VERSION ""

NS_ :

BS_:

BU_: XXX

BO_ 85 CID_FUPSWT: 8 XXX
 SG_ sig_khpeiq : 40|1@1+ (1,0) [0|1] "" XXX
 SG_ sig_ccaecv : 56|8@1+ (1,0) [0|255] "" XXX

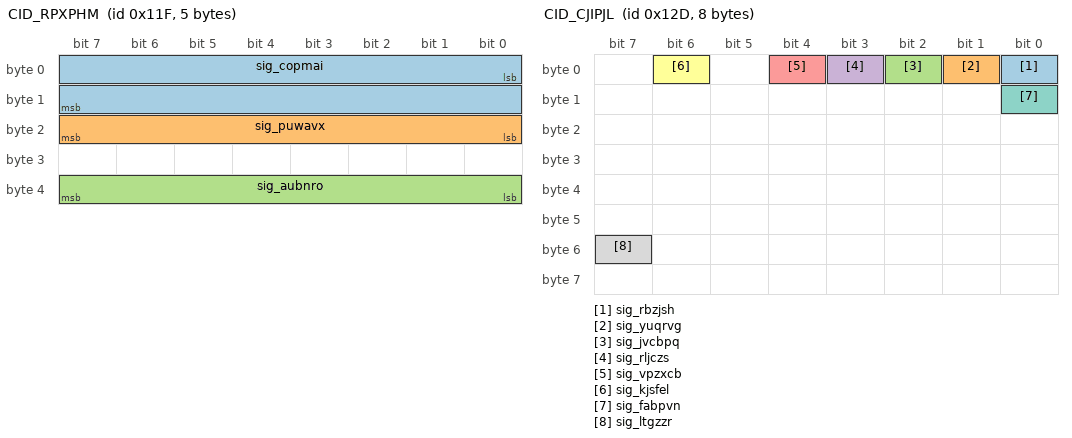
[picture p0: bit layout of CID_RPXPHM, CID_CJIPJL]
BO_ 287 CID_RPXPHM: 5 XXX
 SG_ sig_copmai : 0|16@1- (0.1,0) [-450|450] "" XXX
 SG_ sig_puwavx : 16|8@1+ (4,0) [0|1020] "" XXX
 SG_ sig_aubnro : 32|8@1+ (1,0) [0|255] "" XXX

BO_ 289 CID_MSTLHB: 8 XXX
 SG_ sig_lrkbzq : 0|12@1+ (1,0) [0|255] "" XXX

BO_ 301 CID_CJIPJL: 8 XXX
 SG_ sig_rbzjsh : 0|1@0+ (1,0) [0|1] "" XXX
 SG_ sig_yuqrvg : 1|1@0+ (1,0) [0|1] "" XXX
 SG_ sig_jvcbpq : 2|1@0+ (1,0) [0|1] "" XXX
 SG_ sig_rljczs : 3|1@0+ (1,0) [0|1] "" XXX
 SG_ sig_vpzxcb : 4|1@0+ (1,0) [0|1] "" XXX
 SG_ sig_kjsfel : 6|1@0+ (1,0) [0|1] "" XXX
 SG_ sig_fabpvn : 8|1@0+ (1,0) [0|1] "" XXX
 SG_ sig_ltgzzr : 55|1@0+ (1,0) [0|1] "" XXX

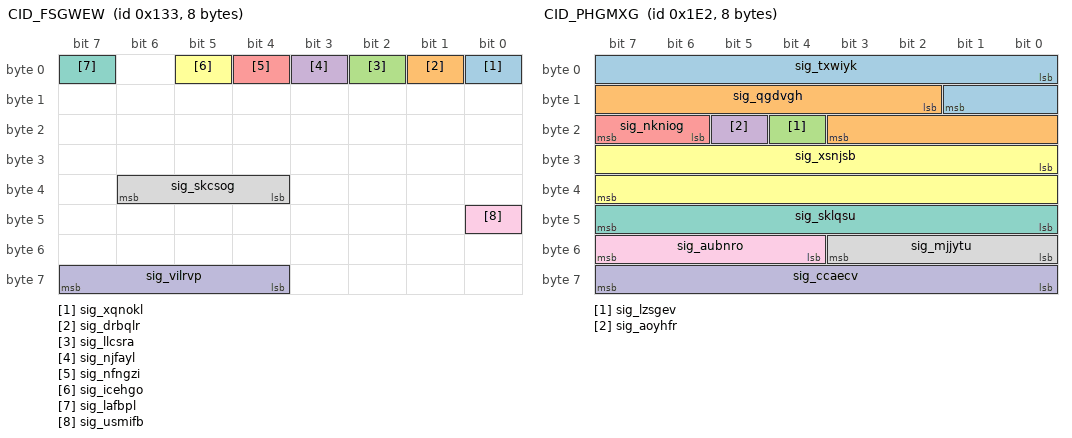
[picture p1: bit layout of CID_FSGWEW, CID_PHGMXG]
BO_ 307 CID_FSGWEW: 8 XXX
 SG_ sig_xqnokl : 0|1@0+ (1,0) [0|1] "" XXX
 SG_ sig_drbqlr : 1|1@1+ (1,0) [0|1] "" XXX
 SG_ sig_llcsra : 2|1@1+ (1,0) [0|1] "" XXX
 SG_ sig_njfayl : 3|1@1+ (1,0) [0|1] "" XXX
 SG_ sig_nfngzi : 4|1@0+ (1,0) [0|1] "" XXX
 SG_ sig_icehgo : 5|1@0+ (1,0) [0|1] "" XXX
 SG_ sig_lafbpl : 7|1@0+ (1,0) [0|1] "" XXX
 SG_ sig_skcsog : 36|3@1+ (1,0) [0|7] "" XXX
 SG_ sig_usmifb : 40|1@0+ (1,0) [0|1] "" XXX
 SG_ sig_vilrvp : 63|4@0+ (1,0) [0|15] "" XXX

BO_ 482 CID_PHGMXG: 8 XXX
 SG_ sig_txwiyk : 0|10@1- (0.01,0) [0|5] "" XXX
 SG_ sig_qgdvgh : 10|10@1- (0.01,0) [-5|0] "" XXX
 SG_ sig_lzsgev : 20|1@0+ (1,0) [0|1] "" XXX
 SG_ sig_aoyhfr : 21|1@0+ (1,0) [0|1] "" XXX
 SG_ sig_nkniog : 22|2@1+ (1,0) [0|1] "" XXX
 SG_ sig_xsnjsb : 24|16@1- (0.1,0) [-780|779.9] "" XXX
 SG_ sig_sklqsu : 47|8@0+ (1,0) [0|255] "" XXX
 SG_ sig_mjjytu : 48|4@1+ (1,0) [0|15] "" XXX
 SG_ sig_aubnro : 52|4@1+ (1,0) [0|15] "" XXX
 SG_ sig_ccaecv : 56|8@1+ (1,0) [0|255] "" XXX

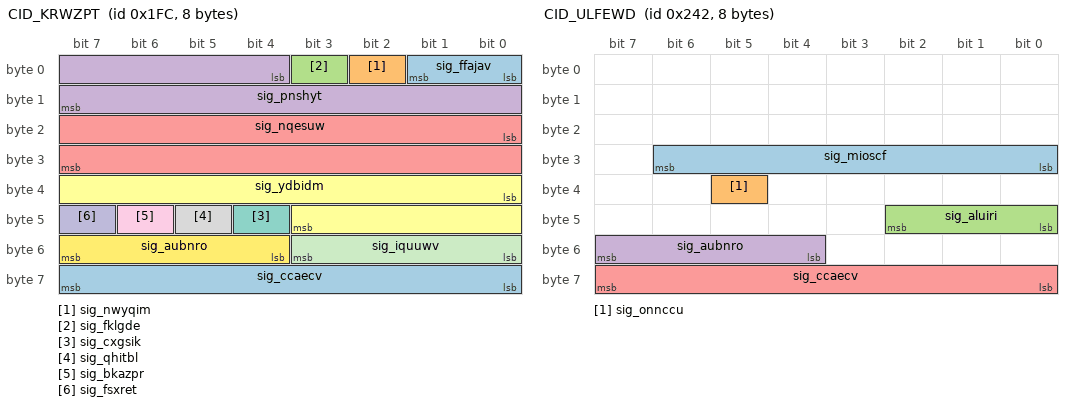
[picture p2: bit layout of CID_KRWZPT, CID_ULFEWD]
BO_ 508 CID_KRWZPT: 8 XXX
 SG_ sig_ffajav : 0|2@1+ (1,0) [0|1] "" XXX
 SG_ sig_nwyqim : 2|1@1+ (1,0) [0|1] "" XXX
 SG_ sig_fklgde : 3|1@0+ (1,0) [0|1] "" XXX
 SG_ sig_pnshyt : 4|12@1- (1,0) [-2048|2047] "" XXX
 SG_ sig_nqesuw : 16|16@1- (0.1,0) [-780|779.9] "Deg" XXX
 SG_ sig_ydbidm : 32|12@1- (0.01,0) [0|63] "" XXX
 SG_ sig_cxgsik : 44|1@0+ (1,0) [0|1] "" XXX
 SG_ sig_qhitbl : 45|1@1+ (1,0) [0|255] "" XXX
 SG_ sig_bkazpr : 46|1@1+ (1,0) [0|1] "" XXX
 SG_ sig_fsxret : 47|1@0+ (1,0) [0|3] "" XXX
 SG_ sig_iquuwv : 48|4@1+ (1,0) [0|15] "" XXX
 SG_ sig_aubnro : 52|4@1+ (1,0) [0|15] "" XXX
 SG_ sig_ccaecv : 56|8@1+ (1,0) [0|255] "" XXX

BO_ 578 CID_ULFEWD: 8 XXX
 SG_ sig_mioscf : 30|7@0+ (1,0) [0|127] "" XXX
 SG_ sig_onnccu : 37|1@0+ (1,0) [0|1] "" XXX
 SG_ sig_aluiri : 40|3@1+ (1,0) [0|7] "" XXX
 SG_ sig_aubnro : 55|4@0+ (1,0) [0|15] "" XXX
 SG_ sig_ccaecv : 56|8@1+ (1,0) [0|255] "" XXX

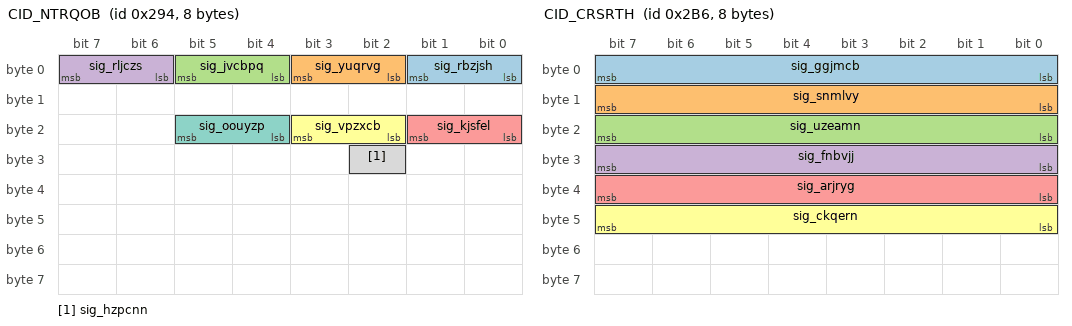
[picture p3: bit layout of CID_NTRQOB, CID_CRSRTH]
BO_ 660 CID_NTRQOB: 8 XXX
 SG_ sig_rbzjsh : 1|2@0+ (1,0) [0|3] "" XXX
 SG_ sig_yuqrvg : 3|2@0+ (1,0) [0|3] "" XXX
 SG_ sig_jvcbpq : 5|2@0+ (1,0) [0|3] "" XXX
 SG_ sig_rljczs : 7|2@0+ (1,0) [0|3] "" XXX
 SG_ sig_kjsfel : 17|2@0+ (1,0) [0|3] "" XXX
 SG_ sig_vpzxcb : 19|2@0+ (1,0) [0|3] "" XXX
 SG_ sig_oouyzp : 21|2@0+ (1,0) [0|3] "" XXX
 SG_ sig_hzpcnn : 26|1@0+ (1,0) [0|1] "" XXX

BO_ 694 CID_CRSRTH: 8 XXX
 SG_ sig_ggjmcb : 7|8@0+ (1,0) [0|255] "" XXX
 SG_ sig_snmlvy : 15|8@0+ (1,0) [0|255] "" XXX
 SG_ sig_uzeamn : 23|8@0+ (1,0) [0|255] "" XXX
 SG_ sig_fnbvjj : 31|8@0+ (1,0) [0|255] "" XXX
 SG_ sig_arjryg : 39|8@0+ (1,0) [0|255] "" XXX
 SG_ sig_ckqern : 47|8@0+ (1,0) [0|255] "" XXX

BO_ 790 CID_AKQXAC: 8 XXX
 SG_ sig_mhqcfa : 3|4@0+ (1,0) [0|1] "" XXX
 SG_ sig_szzntf : 4|2@1+ (1,0) [0|3] "" XXX
 SG_ sig_bfdwya : 6|2@1+ (1,0) [0|3] "" XXX
 SG_ sig_bmkikb : 8|2@1+ (1,0) [0|3] "" XXX
 SG_ sig_znuqhe : 10|1@1+ (1,0) [0|1] "" XXX
 SG_ sig_elygmq : 11|4@1+ (1,0) [0|1] "" XXX
 SG_ sig_vcobfx : 15|1@0+ (1,0) [0|1] "" XXX
 SG_ sig_xsnjsb : 16|11@1- (1,0) [-1024|1023] "" XXX
 SG_ sig_lzsgev : 27|1@1+ (1,0) [0|1] "" XXX
 SG_ sig_aoyhfr : 28|1@1+ (1,0) [0|3] "" XXX
 SG_ sig_pcgoix : 29|1@0+ (1,0) [0|1] "" XXX
 SG_ sig_iuokvo : 30|1@0+ (1,0) [0|1] "" XXX
 SG_ sig_aeodfr : 31|1@0+ (1,0) [0|1] "" XXX
 SG_ sig_twling : 32|2@1+ (1,0) [0|3] "" XXX
 SG_ sig_plttoo : 34|2@1+ (1,0) [0|3] "" XXX
 SG_ sig_azepww : 36|4@1+ (1,0) [0|3] "" XXX
 SG_ sig_navtqm : 40|8@1+ (5,-5) [-5|1270] "" XXX
 SG_ sig_laolyo : 49|2@0+ (1,0) [0|3] "" XXX
 SG_ sig_perogx : 51|2@0+ (1,0) [0|3] "" XXX
 SG_ sig_aubnro : 52|4@1+ (1,0) [0|15] "" XXX
 SG_ sig_ccaecv : 56|8@1+ (1,0) [0|15] "" XXX

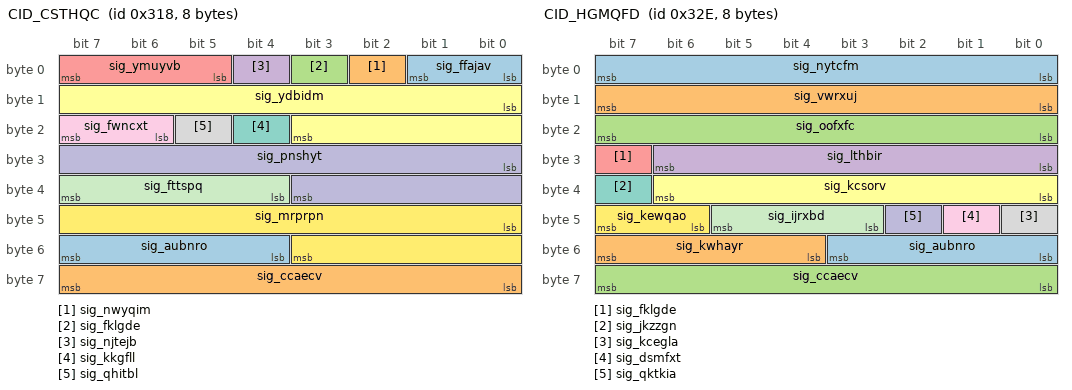
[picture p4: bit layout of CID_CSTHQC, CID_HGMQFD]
BO_ 792 CID_CSTHQC: 8 XXX
 SG_ sig_ffajav : 0|2@1+ (1,0) [0|1] "" XXX
 SG_ sig_nwyqim : 2|1@1+ (1,0) [0|1] "" XXX
 SG_ sig_fklgde : 3|1@1+ (1,0) [0|1] "" XXX
 SG_ sig_njtejb : 4|1@1+ (1,0) [0|1] "" XXX
 SG_ sig_ymuyvb : 5|3@1+ (1,0) [0|1] "" XXX
 SG_ sig_ydbidm : 8|12@1- (1,0) [-2048|2047] "" XXX
 SG_ sig_kkgfll : 20|1@1+ (1,0) [0|1] "" XXX
 SG_ sig_qhitbl : 21|1@1+ (1,0) [0|1] "" XXX
 SG_ sig_fwncxt : 22|2@1+ (1,0) [0|15] "" XXX
 SG_ sig_pnshyt : 24|12@1- (1,0) [-2048|2047] "" XXX
 SG_ sig_fttspq : 36|4@1+ (1,0) [0|15] "" XXX
 SG_ sig_mrprpn : 40|12@1+ (1,0) [0|4095] "" XXX
 SG_ sig_aubnro : 52|4@1+ (1,0) [0|15] "" XXX
 SG_ sig_ccaecv : 56|8@1+ (1,0) [0|255] "" XXX

BO_ 813 CID_YJGMTI: 8 XXX
 SG_ sig_ginhwr : 0|9@1+ (0.5,0) [0|255.5] "" XXX
 SG_ sig_tvsgqb : 9|1@1+ (1,0) [0|1] "" XXX
 SG_ sig_ncymwn : 10|3@1+ (1,0) [0|7] "" XXX
 SG_ sig_urxhdo : 13|3@1+ (1,0) [0|7] "" XXX
 SG_ sig_tgcotr : 16|1@1+ (1,0) [0|1] "" XXX
 SG_ sig_zpaojq : 17|1@1+ (1,0) [0|1] "" XXX
 SG_ sig_fklgde : 18|1@1+ (1,0) [0|1] "" XXX
 SG_ sig_uancac : 19|3@1+ (1,0) [0|1] "" XXX
 SG_ sig_steqoi : 22|1@0+ (1,0) [0|1] "" XXX
 SG_ sig_bkwvyy : 23|1@0+ (1,0) [0|1] "" XXX
 SG_ sig_bmkikb : 24|1@1+ (1,0) [0|1] "" XXX
 SG_ sig_ssfjhn : 25|7@1+ (1,0) [0|127] "" XXX
 SG_ sig_bxhmbj : 32|4@1+ (1,0) [0|15] "" XXX
 SG_ sig_ezfuol : 36|12@1+ (1,0) [0|4095] "" XXX
 SG_ sig_aubnro : 48|4@1+ (1,0) [0|15] "" XXX
 SG_ sig_pblzjk : 55|4@0+ (1,0) [0|15] "" XXX
 SG_ sig_ccaecv : 56|8@1+ (1,0) [0|255] "" XXX

BO_ 814 CID_HGMQFD: 8 XXX
 SG_ sig_nytcfm : 0|8@1+ (0.05,-5) [-100|155] "" XXX
 SG_ sig_vwrxuj : 8|8@1+ (0.05,-5) [0|1.26] "" XXX
 SG_ sig_oofxfc : 16|8@1+ (0.05,-5) [0|1.26] "" XXX
 SG_ sig_lthbir : 24|7@1+ (0.2,0) [0|12.7] "" XXX
 SG_ sig_fklgde : 31|1@0+ (1,0) [0|1] "" XXX
 SG_ sig_kcsorv : 32|7@1+ (0.2,-16) [0|12.7] "" XXX
 SG_ sig_jkzzgn : 39|1@0+ (1,0) [0|1] "" XXX
 SG_ sig_kcegla : 40|1@0+ (1,0) [0|1] "" XXX
 SG_ sig_dsmfxt : 41|1@0+ (1,0) [0|1] "" XXX
 SG_ sig_qktkia : 42|1@1+ (1,0) [0|3] "" XXX
 SG_ sig_ijrxbd : 45|3@0+ (1,0) [0|1] "" XXX
 SG_ sig_kewqao : 46|2@1+ (1,0) [0|3] "" XXX
 SG_ sig_aubnro : 48|4@1+ (1,0) [0|15] "" XXX
 SG_ sig_kwhayr : 55|4@0+ (1,0) [0|15] "" XXX
 SG_ sig_ccaecv : 56|8@1+ (1,0) [0|255] "" XXX

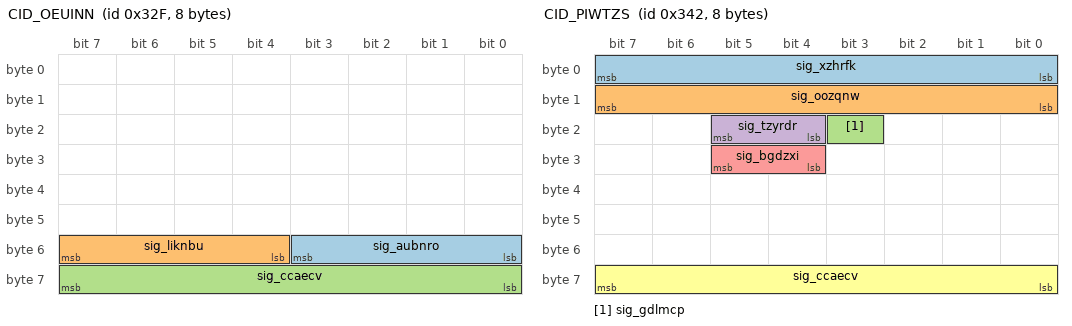
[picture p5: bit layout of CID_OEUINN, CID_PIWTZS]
BO_ 815 CID_OEUINN: 8 XXX
 SG_ sig_aubnro : 48|4@1+ (1,0) [0|15] "" XXX
 SG_ sig_liknbu : 55|4@0+ (1,0) [0|15] "" XXX
 SG_ sig_ccaecv : 56|8@1+ (1,0) [0|255] "" XXX

BO_ 834 CID_PIWTZS: 8 XXX
 SG_ sig_xzhrfk : 0|8@1+ (0.01,0) [0|2.55] "" XXX
 SG_ sig_oozqnw : 8|8@1+ (0.01,0) [0|2.55] "" XXX
 SG_ sig_gdlmcp : 19|1@1+ (1,0) [0|1] "" XXX
 SG_ sig_tzyrdr : 20|2@1+ (1,0) [0|255] "" XXX
 SG_ sig_bgdzxi : 28|2@1+ (1,0) [0|1] "" XXX
 SG_ sig_ccaecv : 56|8@1+ (1,0) [0|255] "" XXX

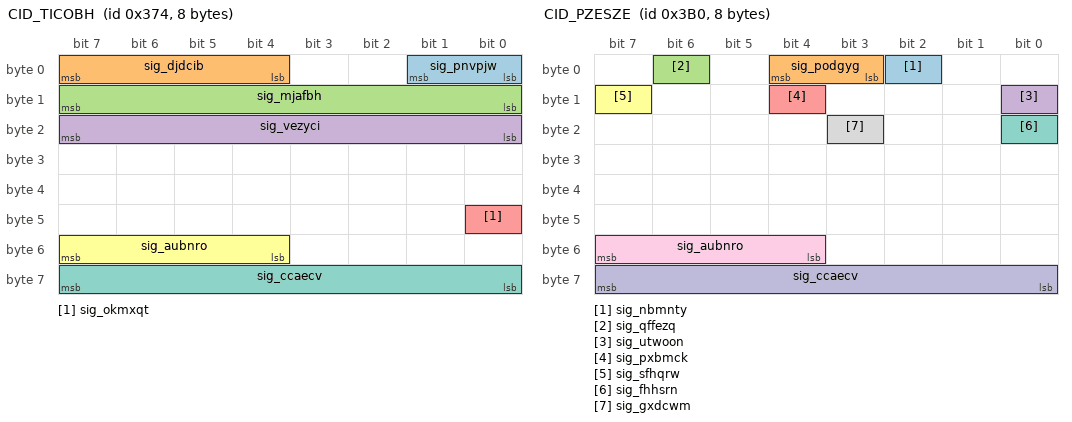
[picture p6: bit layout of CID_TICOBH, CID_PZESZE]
BO_ 884 CID_TICOBH: 8 XXX
 SG_ sig_pnvpjw : 1|2@0+ (1,0) [0|3] "" XXX
 SG_ sig_djdcib : 7|4@0+ (1,0) [0|15] "" XXX
 SG_ sig_mjafbh : 15|8@0+ (0.1,-12) [0|255] "" XXX
 SG_ sig_vezyci : 23|8@0+ (1,-100) [0|255] "" XXX
 SG_ sig_okmxqt : 40|1@0+ (1,0) [0|3] "" XXX
 SG_ sig_aubnro : 52|4@1+ (1,0) [0|15] "" XXX
 SG_ sig_ccaecv : 56|8@1+ (1,0) [0|255] "" XXX

BO_ 944 CID_PZESZE: 8 XXX
 SG_ sig_nbmnty : 2|1@0+ (1,0) [0|1] "" XXX
 SG_ sig_podgyg : 4|2@0+ (1,0) [0|3] "" XXX
 SG_ sig_qffezq : 6|1@0+ (1,0) [0|1] "" XXX
 SG_ sig_utwoon : 8|1@0+ (1,0) [0|1] "" XXX
 SG_ sig_pxbmck : 12|1@0+ (1,0) [0|1] "" XXX
 SG_ sig_sfhqrw : 15|1@0+ (1,0) [0|1] "" XXX
 SG_ sig_fhhsrn : 16|1@0+ (1,0) [0|1] "" XXX
 SG_ sig_gxdcwm : 19|1@0+ (1,0) [0|1] "" XXX
 SG_ sig_aubnro : 52|4@1+ (1,0) [0|15] "" XXX
 SG_ sig_ccaecv : 56|8@1+ (1,0) [0|255] "" XXX

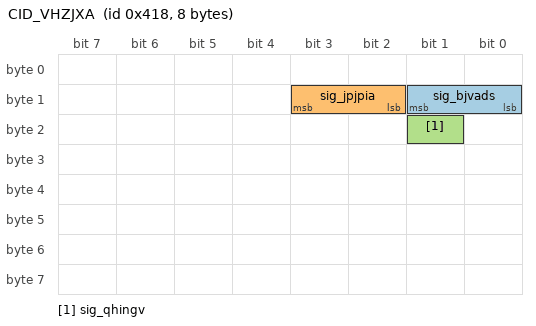
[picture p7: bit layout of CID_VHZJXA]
BO_ 1048 CID_VHZJXA: 8 XXX
 SG_ sig_bjvads : 9|2@0+ (1,0) [0|1] "" XXX
 SG_ sig_jpjpia : 11|2@0+ (1,0) [0|1] "" XXX
 SG_ sig_qhingv : 17|1@0+ (1,0) [0|1] "" XXX

VAL_ 578 sig_aluiri 4 "D" 2 "R" 3 "N" 1 "P";
VAL_ 790 sig_mhqcfa 11 "AutoFullBeamActive" 2 "AutoFullBeamInactive";
VAL_ 790 sig_szzntf 0 "GRAY" 1 "GREEN" 2 "YELLOW" 3 "RED";
VAL_ 790 sig_bfdwya 3 "ALARM_AND_LKA" 2 "LKA" 1 "ALARM" 0 "DISABLE";
VAL_ 790 sig_plttoo 0 "GRAY" 1 "GREEN" 2 "YELLOW" 3 "RED";
VAL_ 790 sig_laolyo 0 "VIBRATION" 1 "AUDIO" 2 "AUDIO_AND_VIBRATION";
VAL_ 792 sig_ffajav 0 "NotReady" 1 "Ready" 2 "Active" 3 "TemporaryFail";
VAL_ 813 sig_ncymwn 4 "4BAR" 3 "3BAR" 2 "2BAR" 1 "1BAR";
VAL_ 813 sig_uancac 0 "OFF" 2 "ACC_ON" 3 "ACC_ACTIVE" 5 "FORCE_ACCEL" 7 "ERROR";
VAL_ 813 sig_ssfjhn 36 "ACC_ERROR" 22 "OVERRIDE" 12 "ENGAGE" 8 "DISENGAGE" 20 "ACC_ON" 32 "ACC_OFF" 48 "CHECK_GEAR_D" 16 "FORCE_ACCEL" 0 "NONE";
VAL_ 814 sig_ijrxbd 0 "Off" 1 "Passive" 2 "StandBy" 3 "ActiveControl" 4 "BrakeOnly" 5 "Override" 6 "Standstill" 7 "Failure";
VAL_ 814 sig_kewqao 0 "Softoff" 1 "Fastoff" 2 "Immediateoff" 3 "Initial";
VAL_ 834 sig_tzyrdr 2 "SPORT" 1 "ECO" 0 "SNOW";
VAL_ 834 sig_bgdzxi 3 "HEV" 2 "FORCE_EV" 1 "EV";
VAL_ 944 sig_podgyg 0 "NOTPRESSED" 1 "DOWN_SETSPEED" 3 "UP_RESETSPEED";
